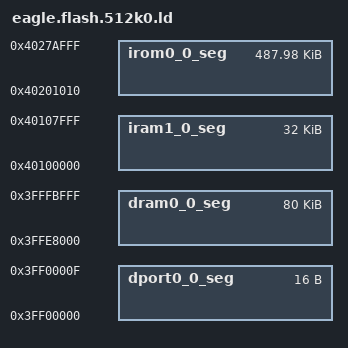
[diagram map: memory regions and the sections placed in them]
/* Flash Split for 512K chips */
/* sketch 487KB */
/* eeprom 20KB */

MEMORY
{
  dport0_0_seg :                        org = 0x3FF00000, len = 0x10
  dram0_0_seg :                         org = 0x3FFE8000, len = 0x14000
  iram1_0_seg :                         org = 0x40100000, len = 0x8000
  irom0_0_seg :                         org = 0x40201010, len = 0x79ff0
}

INCLUDE "../ld/eagle.app.v6.common.ld"
